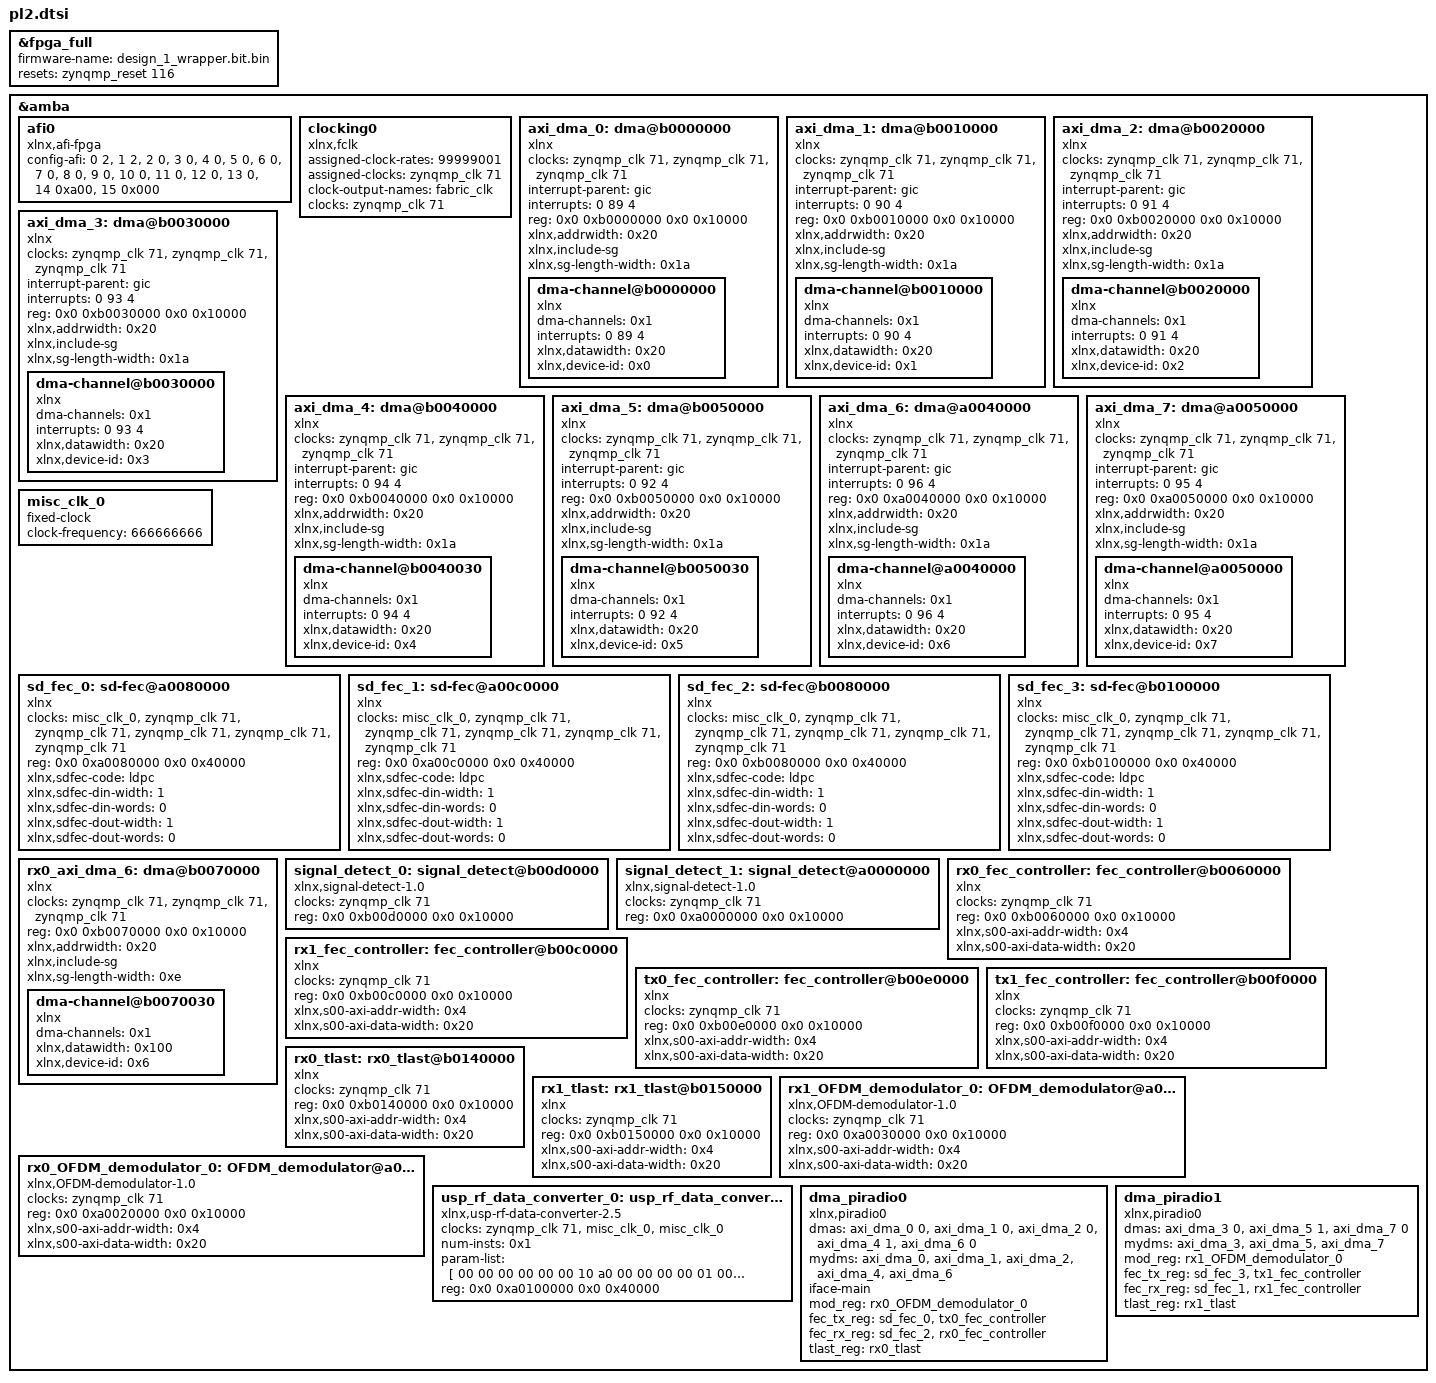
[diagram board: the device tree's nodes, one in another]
/*
 * CAUTION: This file is automatically generated by Xilinx.
 * Version:  
 * Today is: Mon Feb 13 11:20:53 2023
 */


/dts-v1/;
/plugin/;
/ {
	fragment@0 {
		target = <&fpga_full>;
		overlay0: __overlay__ {
			#address-cells = <2>;
			#size-cells = <2>;
			firmware-name = "design_1_wrapper.bit.bin";
			resets = <&zynqmp_reset 116>;
		};
	};
	fragment@1 {
		target = <&amba>;
		overlay1: __overlay__ {
			afi0: afi0 {
				compatible = "xlnx,afi-fpga";
				config-afi = < 0 2>, <1 2>, <2 0>, <3 0>, <4 0>, <5 0>, <6 0>, <7 0>, <8 0>, <9 0>, <10 0>, <11 0>, <12 0>, <13 0>, <14 0xa00>, <15 0x000>;
			};
			clocking0: clocking0 {
				#clock-cells = <0>;
				assigned-clock-rates = <99999001>;
				assigned-clocks = <&zynqmp_clk 71>;
				clock-output-names = "fabric_clk";
				clocks = <&zynqmp_clk 71>;
				compatible = "xlnx,fclk";
			};
		};
	};
	fragment@2 {
		target = <&amba>;
		overlay2: __overlay__ {
			#address-cells = <2>;
			#size-cells = <2>;
			axi_dma_0: dma@b0000000 {
				#dma-cells = <1>;
				clock-names = "s_axi_lite_aclk", "m_axi_sg_aclk", "m_axi_mm2s_aclk";
				clocks = <&zynqmp_clk 71>, <&zynqmp_clk 71>, <&zynqmp_clk 71>;
				compatible = "xlnx";
				interrupt-names = "mm2s_introut";
				interrupt-parent = <&gic>;
				interrupts = <0 89 4>;
				reg = <0x0 0xb0000000 0x0 0x10000>;
				xlnx,addrwidth = <0x20>;
				xlnx,include-sg ;
				xlnx,sg-length-width = <0x1a>;
				dma-channel@b0000000 {
					compatible = "xlnx";
					dma-channels = <0x1>;
					interrupts = <0 89 4>;
					xlnx,datawidth = <0x20>;
					xlnx,device-id = <0x0>;
				};
			};
			axi_dma_1: dma@b0010000 {
				#dma-cells = <1>;
				clock-names = "s_axi_lite_aclk", "m_axi_sg_aclk", "m_axi_mm2s_aclk";
				clocks = <&zynqmp_clk 71>, <&zynqmp_clk 71>, <&zynqmp_clk 71>;
				compatible = "xlnx";
				interrupt-names = "mm2s_introut";
				interrupt-parent = <&gic>;
				interrupts = <0 90 4>;
				reg = <0x0 0xb0010000 0x0 0x10000>;
				xlnx,addrwidth = <0x20>;
				xlnx,include-sg ;
				xlnx,sg-length-width = <0x1a>;
				dma-channel@b0010000 {
					compatible = "xlnx";
					dma-channels = <0x1>;
					interrupts = <0 90 4>;
					xlnx,datawidth = <0x20>;
					xlnx,device-id = <0x1>;
				};
			};
			axi_dma_2: dma@b0020000 {
				#dma-cells = <1>;
				clock-names = "s_axi_lite_aclk", "m_axi_sg_aclk", "m_axi_mm2s_aclk";
				clocks = <&zynqmp_clk 71>, <&zynqmp_clk 71>, <&zynqmp_clk 71>;
				compatible = "xlnx";
				interrupt-names = "mm2s_introut";
				interrupt-parent = <&gic>;
				interrupts = <0 91 4>;
				reg = <0x0 0xb0020000 0x0 0x10000>;
				xlnx,addrwidth = <0x20>;
				xlnx,include-sg ;
				xlnx,sg-length-width = <0x1a>;
				dma-channel@b0020000 {
					compatible = "xlnx";
					dma-channels = <0x1>;
					interrupts = <0 91 4>;
					xlnx,datawidth = <0x20>;
					xlnx,device-id = <0x2>;
				};
			};
			axi_dma_3: dma@b0030000 {
				#dma-cells = <1>;
				clock-names = "s_axi_lite_aclk", "m_axi_sg_aclk", "m_axi_mm2s_aclk";
				clocks = <&zynqmp_clk 71>, <&zynqmp_clk 71>, <&zynqmp_clk 71>;
				compatible = "xlnx";
				interrupt-names = "mm2s_introut";
				interrupt-parent = <&gic>;
				interrupts = <0 93 4>;
				reg = <0x0 0xb0030000 0x0 0x10000>;
				xlnx,addrwidth = <0x20>;
				xlnx,include-sg ;
				xlnx,sg-length-width = <0x1a>;
				dma-channel@b0030000 {
					compatible = "xlnx";
					dma-channels = <0x1>;
					interrupts = <0 93 4>;
					xlnx,datawidth = <0x20>;
					xlnx,device-id = <0x3>;
				};
			};
			axi_dma_4: dma@b0040000 {
				#dma-cells = <1>;
				clock-names = "s_axi_lite_aclk", "m_axi_sg_aclk", "m_axi_s2mm_aclk";
				clocks = <&zynqmp_clk 71>, <&zynqmp_clk 71>, <&zynqmp_clk 71>;
				compatible = "xlnx";
				interrupt-names = "s2mm_introut";
				interrupt-parent = <&gic>;
				interrupts = <0 94 4>;
				reg = <0x0 0xb0040000 0x0 0x10000>;
				xlnx,addrwidth = <0x20>;
				xlnx,include-sg ;
				xlnx,sg-length-width = <0x1a>;
				dma-channel@b0040030 {
					compatible = "xlnx";
					dma-channels = <0x1>;
					interrupts = <0 94 4>;
					xlnx,datawidth = <0x20>;
					xlnx,device-id = <0x4>;
				};
			};
			axi_dma_5: dma@b0050000 {
				#dma-cells = <1>;
				clock-names = "s_axi_lite_aclk", "m_axi_sg_aclk", "m_axi_s2mm_aclk";
				clocks = <&zynqmp_clk 71>, <&zynqmp_clk 71>, <&zynqmp_clk 71>;
				compatible = "xlnx";
				interrupt-names = "s2mm_introut";
				interrupt-parent = <&gic>;
				interrupts = <0 92 4>;
				reg = <0x0 0xb0050000 0x0 0x10000>;
				xlnx,addrwidth = <0x20>;
				xlnx,include-sg ;
				xlnx,sg-length-width = <0x1a>;
				dma-channel@b0050030 {
					compatible = "xlnx";
					dma-channels = <0x1>;
					interrupts = <0 92 4>;
					xlnx,datawidth = <0x20>;
					xlnx,device-id = <0x5>;
				};
			};
			axi_dma_6: dma@a0040000 {
				#dma-cells = <1>;
				clock-names = "s_axi_lite_aclk", "m_axi_sg_aclk", "m_axi_mm2s_aclk";
				clocks = <&zynqmp_clk 71>, <&zynqmp_clk 71>, <&zynqmp_clk 71>;
				compatible = "xlnx";
				interrupt-names = "mm2s_introut";
				interrupt-parent = <&gic>;
				interrupts = <0 96 4>;
				reg = <0x0 0xa0040000 0x0 0x10000>;
				xlnx,addrwidth = <0x20>;
				xlnx,include-sg ;
				xlnx,sg-length-width = <0x1a>;
				dma-channel@a0040000 {
					compatible = "xlnx";
					dma-channels = <0x1>;
					interrupts = <0 96 4>;
					xlnx,datawidth = <0x20>;
					xlnx,device-id = <0x6>;
				};
			};
			axi_dma_7: dma@a0050000 {
				#dma-cells = <1>;
				clock-names = "s_axi_lite_aclk", "m_axi_sg_aclk", "m_axi_mm2s_aclk";
				clocks = <&zynqmp_clk 71>, <&zynqmp_clk 71>, <&zynqmp_clk 71>;
				compatible = "xlnx";
				interrupt-names = "mm2s_introut";
				interrupt-parent = <&gic>;
				interrupts = <0 95 4>;
				reg = <0x0 0xa0050000 0x0 0x10000>;
				xlnx,addrwidth = <0x20>;
				xlnx,include-sg ;
				xlnx,sg-length-width = <0x1a>;
				dma-channel@a0050000 {
					compatible = "xlnx";
					dma-channels = <0x1>;
					interrupts = <0 95 4>;
					xlnx,datawidth = <0x20>;
					xlnx,device-id = <0x7>;
				};
			};
			misc_clk_0: misc_clk_0 {
				#clock-cells = <0>;
				clock-frequency = <666666666>;
				compatible = "fixed-clock";
			};
			sd_fec_0: sd-fec@a0080000 {
				clock-names = "core_clk", "s_axi_aclk", "s_axis_ctrl_aclk", "s_axis_din_aclk", "m_axis_status_aclk", "m_axis_dout_aclk";
				clocks = <&misc_clk_0>, <&zynqmp_clk 71>, <&zynqmp_clk 71>, <&zynqmp_clk 71>, <&zynqmp_clk 71>, <&zynqmp_clk 71>;
				compatible = "xlnx";
				reg = <0x0 0xa0080000 0x0 0x40000>;
				xlnx,sdfec-code = "ldpc";
				xlnx,sdfec-din-width = <1>;
				xlnx,sdfec-din-words = <0>;
				xlnx,sdfec-dout-width = <1>;
				xlnx,sdfec-dout-words = <0>;
			};
			sd_fec_1: sd-fec@a00c0000 {
				clock-names = "core_clk", "s_axi_aclk", "s_axis_ctrl_aclk", "s_axis_din_aclk", "m_axis_status_aclk", "m_axis_dout_aclk";
				clocks = <&misc_clk_0>, <&zynqmp_clk 71>, <&zynqmp_clk 71>, <&zynqmp_clk 71>, <&zynqmp_clk 71>, <&zynqmp_clk 71>;
				compatible = "xlnx";
				reg = <0x0 0xa00c0000 0x0 0x40000>;
				xlnx,sdfec-code = "ldpc";
				xlnx,sdfec-din-width = <1>;
				xlnx,sdfec-din-words = <0>;
				xlnx,sdfec-dout-width = <1>;
				xlnx,sdfec-dout-words = <0>;
			};
			sd_fec_2: sd-fec@b0080000 {
				clock-names = "core_clk", "s_axi_aclk", "s_axis_ctrl_aclk", "s_axis_din_aclk", "m_axis_status_aclk", "m_axis_dout_aclk";
				clocks = <&misc_clk_0>, <&zynqmp_clk 71>, <&zynqmp_clk 71>, <&zynqmp_clk 71>, <&zynqmp_clk 71>, <&zynqmp_clk 71>;
				compatible = "xlnx";
				reg = <0x0 0xb0080000 0x0 0x40000>;
				xlnx,sdfec-code = "ldpc";
				xlnx,sdfec-din-width = <1>;
				xlnx,sdfec-din-words = <0>;
				xlnx,sdfec-dout-width = <1>;
				xlnx,sdfec-dout-words = <0>;
			};
			sd_fec_3: sd-fec@b0100000 {
				clock-names = "core_clk", "s_axi_aclk", "s_axis_ctrl_aclk", "s_axis_din_aclk", "m_axis_status_aclk", "m_axis_dout_aclk";
				clocks = <&misc_clk_0>, <&zynqmp_clk 71>, <&zynqmp_clk 71>, <&zynqmp_clk 71>, <&zynqmp_clk 71>, <&zynqmp_clk 71>;
				compatible = "xlnx";
				reg = <0x0 0xb0100000 0x0 0x40000>;
				xlnx,sdfec-code = "ldpc";
				xlnx,sdfec-din-width = <1>;
				xlnx,sdfec-din-words = <0>;
				xlnx,sdfec-dout-width = <1>;
				xlnx,sdfec-dout-words = <0>;
			};
			rx0_axi_dma_6: dma@b0070000 {
				#dma-cells = <1>;
				clock-names = "s_axi_lite_aclk", "m_axi_sg_aclk", "m_axi_s2mm_aclk";
				clocks = <&zynqmp_clk 71>, <&zynqmp_clk 71>, <&zynqmp_clk 71>;
				compatible = "xlnx";
				reg = <0x0 0xb0070000 0x0 0x10000>;
				xlnx,addrwidth = <0x20>;
				xlnx,include-sg ;
				xlnx,sg-length-width = <0xe>;
				dma-channel@b0070030 {
					compatible = "xlnx";
					dma-channels = <0x1>;
					xlnx,datawidth = <0x100>;
					xlnx,device-id = <0x6>;
				};
			};
			signal_detect_0: signal_detect@b00d0000 {
				clock-names = "clk";
				clocks = <&zynqmp_clk 71>;
				compatible = "xlnx,signal-detect-1.0";
				reg = <0x0 0xb00d0000 0x0 0x10000>;
			};
			signal_detect_1: signal_detect@a0000000 {
				clock-names = "clk";
				clocks = <&zynqmp_clk 71>;
				compatible = "xlnx,signal-detect-1.0";
				reg = <0x0 0xa0000000 0x0 0x10000>;
			};
			rx0_fec_controller: fec_controller@b0060000 {
				clock-names = "axis_aclk";
				clocks = <&zynqmp_clk 71>;
				compatible = "xlnx";
				reg = <0x0 0xb0060000 0x0 0x10000>;
				xlnx,s00-axi-addr-width = <0x4>;
				xlnx,s00-axi-data-width = <0x20>;
			};
			rx1_fec_controller: fec_controller@b00c0000 {
				clock-names = "axis_aclk";
				clocks = <&zynqmp_clk 71>;
				compatible = "xlnx";
				reg = <0x0 0xb00c0000 0x0 0x10000>;
				xlnx,s00-axi-addr-width = <0x4>;
				xlnx,s00-axi-data-width = <0x20>;
			};
			tx0_fec_controller: fec_controller@b00e0000 {
				clock-names = "axis_aclk";
				clocks = <&zynqmp_clk 71>;
				compatible = "xlnx";
				reg = <0x0 0xb00e0000 0x0 0x10000>;
				xlnx,s00-axi-addr-width = <0x4>;
				xlnx,s00-axi-data-width = <0x20>;
			};
			tx1_fec_controller: fec_controller@b00f0000 {
				clock-names = "axis_aclk";
				clocks = <&zynqmp_clk 71>;
				compatible = "xlnx";
				reg = <0x0 0xb00f0000 0x0 0x10000>;
				xlnx,s00-axi-addr-width = <0x4>;
				xlnx,s00-axi-data-width = <0x20>;
			};
			rx0_tlast: rx0_tlast@b0140000 {
				clock-names = "axis_aclk";
				clocks = <&zynqmp_clk 71>;
				compatible = "xlnx";
				reg = <0x0 0xb0140000 0x0 0x10000>;
				xlnx,s00-axi-addr-width = <0x4>;
				xlnx,s00-axi-data-width = <0x20>;
			};
			rx1_tlast: rx1_tlast@b0150000 {
				clock-names = "axis_aclk";
				clocks = <&zynqmp_clk 71>;
				compatible = "xlnx";
				reg = <0x0 0xb0150000 0x0 0x10000>;
				xlnx,s00-axi-addr-width = <0x4>;
				xlnx,s00-axi-data-width = <0x20>;
			};
			rx1_OFDM_demodulator_0: OFDM_demodulator@a0030000 {
				clock-names = "axis_aclk";
				clocks = <&zynqmp_clk 71>;
				compatible = "xlnx,OFDM-demodulator-1.0";
				reg = <0x0 0xa0030000 0x0 0x10000>;
				xlnx,s00-axi-addr-width = <0x4>;
				xlnx,s00-axi-data-width = <0x20>;
			};
			rx0_OFDM_demodulator_0: OFDM_demodulator@a0020000 {
				clock-names = "axis_aclk";
				clocks = <&zynqmp_clk 71>;
				compatible = "xlnx,OFDM-demodulator-1.0";
				reg = <0x0 0xa0020000 0x0 0x10000>;
				xlnx,s00-axi-addr-width = <0x4>;
				xlnx,s00-axi-data-width = <0x20>;
			};
			usp_rf_data_converter_0: usp_rf_data_converter@a0100000 {
                                clock-names = "s_axi_aclk", "m0_axis_aclk", "s1_axis_aclk";
                                clocks = <&zynqmp_clk 71>, <&misc_clk_0>, <&misc_clk_0>;
                                compatible = "xlnx,usp-rf-data-converter-2.5";
                                num-insts = <0x1>;
                                param-list = [ 00 00 00 00 00 00 10 a0 00 00 00 00 01 00 00 00 00 00 00 00 00 00 00 00 01 00 00 00 01 00 00 00 00 00 00 00 01 00 00 00 00 00 00 00 00 00 00 00 9a 99 99 99 99 99 19 40 00 00 00 00 00 00 b9 40 00 00 00 00 00 00 00 00 0a 00 00 00 02 00 00 00 01 00 00 00 00 00 00 00 9e ef a7 c6 4b 37 1a 40 04 00 00 00 00 00 00 00 00 00 00 00 02 00 00 00 00 00 00 00 00 00 00 00 00 00 00 00 02 00 00 00 00 00 00 00 00 00 00 00 00 00 00 00 02 00 00 00 00 00 00 00 00 00 00 00 00 00 00 00 02 00 00 00 00 00 00 00 00 00 00 00 10 00 00 00 00 00 00 00 00 00 00 00 00 00 00 00 03 00 00 00 00 00 00 00 10 00 00 00 00 00 00 00 00 00 00 00 00 00 00 00 03 00 00 00 00 00 00 00 10 00 00 00 00 00 00 00 00 00 00 00 00 00 00 00 03 00 00 00 00 00 00 00 10 00 00 00 00 00 00 00 00 00 00 00 00 00 00 00 03 00 00 00 01 00 00 00 00 00 00 00 0f d6 ff 39 cc 97 f7 3f 0a d7 a3 70 3d 0a 97 40 0a d7 a3 70 3d 0a 57 40 0a 00 00 00 06 00 00 00 01 00 00 00 00 00 00 00 9e ef a7 c6 4b 37 1a 40 04 00 00 00 00 00 00 00 00 00 00 00 02 00 00 00 00 00 00 00 00 00 00 00 00 00 00 00 02 00 00 00 00 00 00 00 01 00 00 00 00 00 00 00 00 00 00 00 00 00 00 00 01 00 00 00 01 00 00 00 00 00 00 00 00 00 00 00 00 00 00 00 10 00 00 00 00 00 00 00 00 00 00 00 00 00 00 00 03 00 00 00 00 00 00 00 10 00 00 00 00 00 00 00 00 00 00 00 00 00 00 00 03 00 00 00 00 00 00 00 08 00 00 00 04 00 00 00 00 00 00 00 00 00 00 00 01 00 00 00 00 00 00 00 08 00 00 00 04 00 00 00 00 00 00 00 00 00 00 00 01 00 00 00 00 00 00 00 00 00 00 00 9a 99 99 99 99 99 19 40 00 00 00 00 00 00 b9 40 00 00 00 00 00 00 00 00 0a 00 00 00 02 00 00 00 01 00 00 00 00 00 00 00 9e ef a7 c6 4b 37 1a 40 00 00 00 00 00 00 00 00 00 00 00 00 02 00 00 00 00 00 00 00 00 00 00 00 00 00 00 00 02 00 00 00 00 00 00 00 00 00 00 00 00 00 00 00 02 00 00 00 00 00 00 00 00 00 00 00 00 00 00 00 02 00 00 00 00 00 00 00 00 00 00 00 10 00 00 00 00 00 00 00 00 00 00 00 00 00 00 00 03 00 00 00 00 00 00 00 10 00 00 00 00 00 00 00 00 00 00 00 00 00 00 00 03 00 00 00 00 00 00 00 10 00 00 00 00 00 00 00 00 00 00 00 00 00 00 00 03 00 00 00 00 00 00 00 10 00 00 00 00 00 00 00 00 00 00 00 00 00 00 00 03 00 00 00 00 00 00 00 00 00 00 00 9a 99 99 99 99 99 19 40 00 00 00 00 00 00 b9 40 00 00 00 00 00 00 00 00 0a 00 00 00 02 00 00 00 01 00 00 00 00 00 00 00 9e ef a7 c6 4b 37 1a 40 00 00 00 00 00 00 00 00 00 00 00 00 02 00 00 00 00 00 00 00 00 00 00 00 00 00 00 00 02 00 00 00 00 00 00 00 00 00 00 00 00 00 00 00 02 00 00 00 00 00 00 00 00 00 00 00 00 00 00 00 02 00 00 00 00 00 00 00 00 00 00 00 10 00 00 00 00 00 00 00 00 00 00 00 00 00 00 00 03 00 00 00 00 00 00 00 10 00 00 00 00 00 00 00 00 00 00 00 00 00 00 00 03 00 00 00 00 00 00 00 10 00 00 00 00 00 00 00 00 00 00 00 00 00 00 00 03 00 00 00 00 00 00 00 10 00 00 00 00 00 00 00 00 00 00 00 00 00 00 00 03 00 00 00 01 00 00 00 00 00 00 00 0f d6 ff 39 cc 97 f7 3f 0a d7 a3 70 3d 0a 97 40 0a d7 a3 70 3d 0a 57 40 0a 00 00 00 01 00 00 00 01 00 00 00 00 00 00 00 fc a9 f1 d2 4d 62 10 40 02 00 00 00 01 00 00 00 00 00 00 00 01 00 00 00 00 00 00 00 01 00 00 00 00 00 00 00 01 00 00 00 00 00 00 00 01 00 00 00 04 00 00 00 04 00 00 00 00 00 00 00 01 00 00 00 01 00 00 00 04 00 00 00 04 00 00 00 00 00 00 00 01 00 00 00 01 00 00 00 04 00 00 00 04 00 00 00 00 00 00 00 01 00 00 00 01 00 00 00 04 00 00 00 04 00 00 00 00 00 00 00 01 00 00 00 00 00 00 00 00 00 00 00 00 00 00 00 00 00 00 40 00 00 00 00 00 40 9f 40 00 00 00 00 00 00 00 00 0a 00 00 00 01 00 00 00 01 00 00 00 00 00 00 00 fc a9 f1 d2 4d 62 10 40 02 00 00 00 00 00 00 00 02 00 00 00 00 00 00 00 02 00 00 00 00 00 00 00 02 00 00 00 00 00 00 00 02 00 00 00 00 00 00 00 08 00 00 00 00 00 00 00 00 00 00 00 03 00 00 00 00 00 00 00 08 00 00 00 00 00 00 00 00 00 00 00 03 00 00 00 00 00 00 00 08 00 00 00 00 00 00 00 00 00 00 00 03 00 00 00 00 00 00 00 08 00 00 00 00 00 00 00 00 00 00 00 03 00 00 00 00 00 00 00 00 00 00 00 00 00 00 00 00 00 00 40 00 00 00 00 00 40 9f 40 00 00 00 00 00 00 00 00 0a 00 00 00 01 00 00 00 01 00 00 00 00 00 00 00 fc a9 f1 d2 4d 62 10 40 02 00 00 00 00 00 00 00 02 00 00 00 00 00 00 00 02 00 00 00 00 00 00 00 02 00 00 00 00 00 00 00 02 00 00 00 00 00 00 00 08 00 00 00 00 00 00 00 00 00 00 00 03 00 00 00 00 00 00 00 08 00 00 00 00 00 00 00 00 00 00 00 03 00 00 00 00 00 00 00 08 00 00 00 00 00 00 00 00 00 00 00 03 00 00 00 00 00 00 00 08 00 00 00 00 00 00 00 00 00 00 00 03 00 00 00 00 00 00 00 00 00 00 00 00 00 00 00 00 00 00 40 00 00 00 00 00 40 9f 40 00 00 00 00 00 00 00 00 0a 00 00 00 01 00 00 00 01 00 00 00 00 00 00 00 fc a9 f1 d2 4d 62 10 40 02 00 00 00 00 00 00 00 02 00 00 00 00 00 00 00 02 00 00 00 00 00 00 00 02 00 00 00 00 00 00 00 02 00 00 00 00 00 00 00 08 00 00 00 00 00 00 00 00 00 00 00 03 00 00 00 00 00 00 00 08 00 00 00 00 00 00 00 00 00 00 00 03 00 00 00 00 00 00 00 08 00 00 00 00 00 00 00 00 00 00 00 03 00 00 00 00 00 00 00 08 00 00 00 00 00 00 00 00 00 00 00 03 00 00 00];
                                reg = <0x0 0xa0100000 0x0 0x40000>;
                        };
			dma_piradio0: dma_piradio0{
				compatible ="xlnx,piradio0";
				dmas = <&axi_dma_0 0
								&axi_dma_1 0
								&axi_dma_2 0
								&axi_dma_4 1
								&axi_dma_6 0>;
				dma-names = "piradio0_tx", "piradio0_config", "piradio0_config_corr", "piradio0_rx", "piradio0_framer_ctrl", "piradio0_fec_tx_ctrl";
				mydms = <&axi_dma_0 &axi_dma_1 &axi_dma_2 &axi_dma_4 &axi_dma_6>;
				iface-main;
				mod_reg = <&rx0_OFDM_demodulator_0>;
				fec_tx_reg =  <&sd_fec_0 &tx0_fec_controller>;
				fec_rx_reg =  <&sd_fec_2 &rx0_fec_controller>;
				tlast_reg = <&rx0_tlast>;
			};
			dma_piradio1: dma_piradio1{
				compatible ="xlnx,piradio0";
				dmas = <&axi_dma_3 0
						&axi_dma_5 1
						&axi_dma_7 0>;
				dma-names = "piradio0_tx", "piradio0_rx", "piradio0_framer_ctrl";
				mydms = <&axi_dma_3 &axi_dma_5 &axi_dma_7>;
				mod_reg = <&rx1_OFDM_demodulator_0>;
				fec_tx_reg =  <&sd_fec_3 &tx1_fec_controller>;
				fec_rx_reg =  <&sd_fec_1 &rx1_fec_controller>;
				tlast_reg = <&rx1_tlast>;
			};
		};
	};
};
